# SSI register map
Vendor: Texas Instruments
Peripheral module from a debugger description file (folder CC2650).
Registers are 32-bit, access per field, reset 0x0 unless marked. A register's access mark holds for its fields unless they carry their own. Offsets are as the file gives them; lines under a group give offsets from that group; [hi:lo] are bit positions; {n}, {i} and the like mark numbered series; 'fields as' and 'values as' point back to an identical list; <NAME> marks a mode.

## SSI — Synchronous Serial Interface with master and slave capabilities
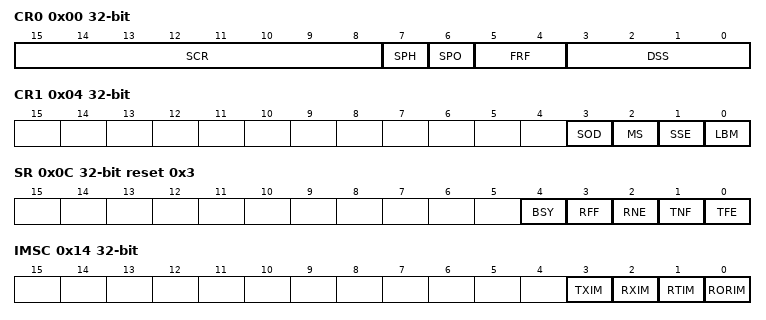
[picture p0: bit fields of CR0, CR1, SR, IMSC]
0x00 CR0 — Control 0
  [15:8] SCR rw — Serial clock rate: This is used to generate the transmit and receive bit rate of the SSI. The bit rate is (SSI's clock frequency)/((SCR+1)*CPSR.CPSDVSR). SCR is a value from 0-255.
  [7] SPH rw — CLKOUT phase (Motorola SPI frame format only) This bit selects the clock edge that captures data and enables it to change state. It has the most impact on the first bit transmitted by either permitting or not permitting a clock transition before the first data capture edge.
    1=2ND_CLK_EDGE (Data is captured on the second clock edge transition.); 0=1ST_CLK_EDGE (Data is captured on the first clock edge transition.)
  [6] SPO rw — CLKOUT polarity (Motorola SPI frame format only)
    1=HIGH (SSI produces a steady state HIGH value on the CLKOUT pin when data is not being transferred.); 0=LOW (SSI produces a steady state LOW value on the CLKOUT pin when data is not being transferred.)
  [5:4] FRF rw — Frame format. The supported frame formats are Motorola SPI, TI synchronous serial and National Microwire. Value 0'b11 is reserved and shall not be used.
    2=NATIONAL_MICROWIRE (National Microwire frame format); 1=TI_SYNC_SERIAL (TI synchronous serial frame format); 0=MOTOROLA_SPI (Motorola SPI frame format)
  [3:0] DSS rw — Data Size Select. Values 0b0000, 0b0001, 0b0010 and 0b0011 are reserved and shall not be used.
    {v}={v+1}_BIT ({v+1}-bit data) (v=3..15)
0x04 CR1 — Control 1
  [3] SOD rw — Slave-mode output disabled This bit is relevant only in the slave mode, MS=1. In multiple-slave systems, it is possible for an SSI master to broadcast a message to all slaves in the system while ensuring that only one slave drives data onto its serial output line. In such systems the RXD lines from multiple slaves could be tied together. To operate in such systems, this bitfield can be set if the SSI slave is not supposed to drive the TXD line: 0: SSI can drive the TXD output in slave mode. 1: SSI cannot drive the TXD output in slave mode.
  [2] MS rw — Master or slave mode select. This bit can be modified only when SSI is disabled, SSE=0.
    1=SLAVE (Device configured as slave); 0=MASTER (Device configured as master)
  [1] SSE rw — Synchronous serial interface enable.
    1=SSI_ENABLED (Operation enabled); 0=SSI_DISABLED (Operation disabled)
  [0] LBM rw — Loop back mode: 0: Normal serial port operation enabled. 1: Output of transmit serial shifter is connected to input of receive serial shifter internally.
0x08 DR — Data 16-bits wide data register: When read, the entry in the receive FIFO, pointed to by the current FIFO read pointer, is accessed. As data values are removed by the receive logic from the incoming data frame, they are placed into the entry in the receive FIFO, pointed to by the current FIFO write pointer. When written, the entry in the transmit FIFO, pointed to by the write pointer, is written to. Data values are removed from the transmit FIFO one value at a time by the transmit logic. It is loaded into the transmit serial shifter, then serially shifted out onto the TXD output pin at the programmed bit rate. When a data size of less than 16 bits is selected, the user must right-justify data written to the transmit FIFO. The transmit logic ignores the unused bits. Received data less than 16 bits is automatically right-justified in the receive buffer.
  [15:0] DATA rw — Transmit/receive data The values read from this field or written to this field must be right-justified when SSI is programmed for a data size that is less than 16 bits (CR0.DSS != 0b1111). Unused bits at the top are ignored by transmit logic. The receive logic automatically right-justifies.
0x0C SR ro reset 0x3 — Status
  [4] BSY — Serial interface busy: 0: SSI is idle 1: SSI is currently transmitting and/or receiving a frame or the transmit FIFO is not empty.
  [3] RFF — Receive FIFO full: 0: Receive FIFO is not full. 1: Receive FIFO is full.
  [2] RNE — Receive FIFO not empty 0: Receive FIFO is empty. 1: Receive FIFO is not empty.
  [1] TNF — Transmit FIFO not full: 0: Transmit FIFO is full. 1: Transmit FIFO is not full.
  [0] TFE — Transmit FIFO empty: 0: Transmit FIFO is not empty. 1: Transmit FIFO is empty.
0x10 CPSR — Clock Prescale
  [7:0] CPSDVSR rw — Clock prescale divisor: This field specifies the division factor by which the input system clock to SSI must be internally divided before further use. The value programmed into this field must be an even non-zero number (2-254). The least significant bit of the programmed number is hard-coded to zero. If an odd number is written to this register, data read back from this register has the least significant bit as zero.
0x14 IMSC — Interrupt Mask Set and Clear
  [3] TXIM rw — Transmit FIFO interrupt mask: A read returns the current mask for transmit FIFO interrupt. On a write of 1, the mask for transmit FIFO interrupt is set which means the interrupt state will be reflected in MIS.TXMIS. A write of 0 clears the mask which means MIS.TXMIS will not reflect the interrupt.
  [2] RXIM rw — Receive FIFO interrupt mask: A read returns the current mask for receive FIFO interrupt. On a write of 1, the mask for receive FIFO interrupt is set which means the interrupt state will be reflected in MIS.RXMIS. A write of 0 clears the mask which means MIS.RXMIS will not reflect the interrupt.
  [1] RTIM rw — Receive timeout interrupt mask: A read returns the current mask for receive timeout interrupt. On a write of 1, the mask for receive timeout interrupt is set which means the interrupt state will be reflected in MIS.RTMIS. A write of 0 clears the mask which means MIS.RTMIS will not reflect the interrupt.
  [0] RORIM rw — Receive overrun interrupt mask: A read returns the current mask for receive overrun interrupt. On a write of 1, the mask for receive overrun interrupt is set which means the interrupt state will be reflected in MIS.RORMIS. A write of 0 clears the mask which means MIS.RORMIS will not reflect the interrupt.
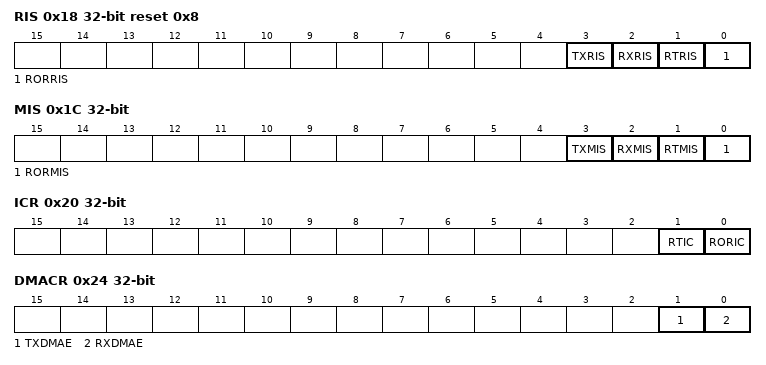
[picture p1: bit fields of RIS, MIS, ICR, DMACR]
0x18 RIS ro reset 0x8 — Raw Interrupt Status
  [3] TXRIS — Raw transmit FIFO interrupt status: The transmit interrupt is asserted when there are four or fewer valid entries in the transmit FIFO. The transmit interrupt is not qualified with the SSI enable signal. Therefore one of the following ways can be used: - data can be written to the transmit FIFO prior to enabling the SSI and the interrupts. - SSI and interrupts can be enabled so that data can be written to the transmit FIFO by an interrupt service routine.
  [2] RXRIS — Raw interrupt state of receive FIFO interrupt: The receive interrupt is asserted when there are four or more valid entries in the receive FIFO.
  [1] RTRIS — Raw interrupt state of receive timeout interrupt: The receive timeout interrupt is asserted when the receive FIFO is not empty and SSI has remained idle for a fixed 32 bit period. This mechanism can be used to notify the user that data is still present in the receive FIFO and requires servicing. This interrupt is deasserted if the receive FIFO becomes empty by subsequent reads, or if new data is received on RXD. It can also be cleared by writing to ICR.RTIC.
  [0] RORRIS — Raw interrupt state of receive overrun interrupt: The receive overrun interrupt is asserted when the FIFO is already full and an additional data frame is received, causing an overrun of the FIFO. Data is over-written in the receive shift register, but not the FIFO so the FIFO contents stay valid. It can also be cleared by writing to ICR.RORIC.
0x1C MIS ro — Masked Interrupt Status
  [3] TXMIS — Masked interrupt state of transmit FIFO interrupt: This field returns the masked interrupt state of transmit FIFO interrupt which is the AND product of raw interrupt state RIS.TXRIS and the mask setting IMSC.TXIM.
  [2] RXMIS — Masked interrupt state of receive FIFO interrupt: This field returns the masked interrupt state of receive FIFO interrupt which is the AND product of raw interrupt state RIS.RXRIS and the mask setting IMSC.RXIM.
  [1] RTMIS — Masked interrupt state of receive timeout interrupt: This field returns the masked interrupt state of receive timeout interrupt which is the AND product of raw interrupt state RIS.RTRIS and the mask setting IMSC.RTIM.
  [0] RORMIS — Masked interrupt state of receive overrun interrupt: This field returns the masked interrupt state of receive overrun interrupt which is the AND product of raw interrupt state RIS.RORRIS and the mask setting IMSC.RORIM.
0x20 ICR wo — Interrupt Clear On a write of 1, the corresponding interrupt is cleared. A write of 0 has no effect.
  [1] RTIC — Clear the receive timeout interrupt: Writing 1 to this field clears the timeout interrupt (RIS.RTRIS). Writing 0 has no effect.
  [0] RORIC — Clear the receive overrun interrupt: Writing 1 to this field clears the overrun error interrupt (RIS.RORRIS). Writing 0 has no effect.
0x24 DMACR — DMA Control
  [1] TXDMAE rw — Transmit DMA enable. If this bit is set to 1, DMA for the transmit FIFO is enabled.
  [0] RXDMAE rw — Receive DMA enable. If this bit is set to 1, DMA for the receive FIFO is enabled.
